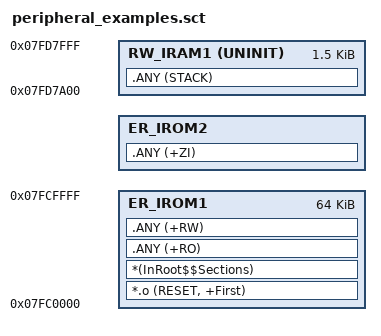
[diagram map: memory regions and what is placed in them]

LR_IROM1 0x07FC0000 0x00018000  {

    ER_IROM1 0x07FC0000 0x00010000  {
        *.o (RESET, +First)
        *(InRoot$$Sections)
        .ANY (+RO)
        .ANY (+RW)
    }
  
    ER_IROM2 +0  {
     .ANY (+ZI)
    }

    RW_IRAM1 (0x07FD8000 - 0x600) UNINIT 0x600 {         ; Stack
        .ANY (STACK)
    }

}

